# STM32H523 register map
File version: 1.2
CPU: CM33 r0p0, little endian, MPU, FPU, 4 interrupt priority bits
Registers are 32-bit, read-write, reset 0x0 unless marked. A register's access mark holds for its fields unless they carry their own. Offsets are from the block's base; [hi:lo] are bit positions; {n}, {i} and the like mark numbered series.

## DLYBOS1 — DLYB address block description
Base 0x4600F000
Same registers: DLYBSD1 0x46008400, DLYBSD1_S 0x56008400, DLYBOS1_S 0x5600F000
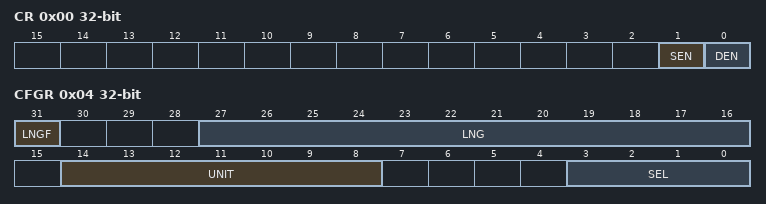
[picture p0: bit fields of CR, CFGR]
0x00 CR — DLYB control register
  [1] SEN — Sampler length enable bit
  [0] DEN — Delay block enable bit
0x04 CFGR — DLYB configuration register
  [31] LNGF ro — Length valid flag
  [27:16] LNG ro — Delay line length value
  [14:8] UNIT — Delay of a unit delay cell.
  [3:0] SEL — Phase for the output clock.

## DTS — DTS address block description
Base 0x40008C00
Same registers: DTS_S 0x50008C00
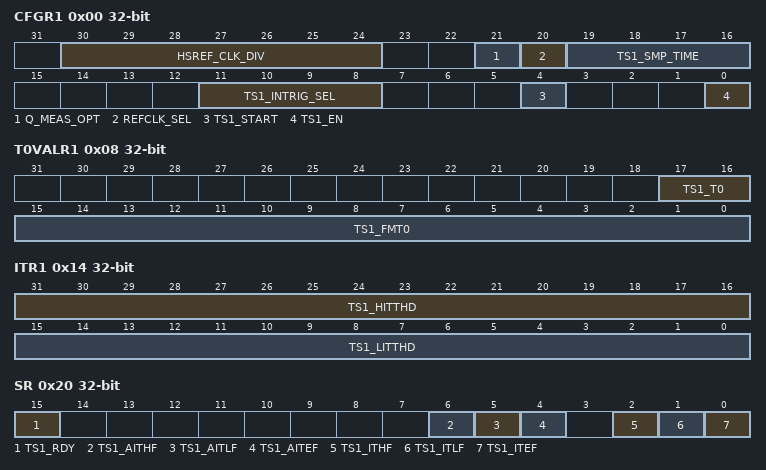
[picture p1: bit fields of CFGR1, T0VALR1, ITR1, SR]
0x00 CFGR1 — Temperature sensor configuration register 1
  [30:24] HSREF_CLK_DIV — High speed clock division ratio
  [21] Q_MEAS_OPT — Quick measurement option bit
  [20] REFCLK_SEL — Reference clock selection bit
  [19:16] TS1_SMP_TIME — Sampling time for temperature sensor 1
  [11:8] TS1_INTRIG_SEL — Input trigger selection bit for temperature sensor 1
  [4] TS1_START — Start frequency measurement on temperature sensor 1
  [0] TS1_EN — Temperature sensor 1 enable bit
0x08 T0VALR1 ro (reset mask 0xFFF00000) — Temperature sensor T0 value register 1
  [17:16] TS1_T0 — Engineering value of the T0 temperature for temperature sensor 1.
  [15:0] TS1_FMT0 — Engineering value of the frequency measured at T0 for
0x10 RAMPVALR ro reset not defined — Temperature sensor ramp value register
  [15:0] TS1_RAMP_COEFF — Engineering value of the ramp coefficient for the temperature sensor 1.
0x14 ITR1 — Temperature sensor interrupt threshold register 1
  [31:16] TS1_HITTHD — High interrupt threshold for temperature sensor 1
  [15:0] TS1_LITTHD — Low interrupt threshold for temperature sensor 1
0x1C DR — Temperature sensor data register
  [15:0] TS1_MFREQ — Value of the counter output value for temperature sensor 1
0x20 SR ro — Temperature sensor status register
  [15] TS1_RDY — Temperature sensor 1 ready flag
  [6] TS1_AITHF — Asynchronous interrupt flag for high threshold on temperature sensor 1
  [5] TS1_AITLF — Asynchronous interrupt flag for low threshold on temperature sensor 1
  [4] TS1_AITEF — Asynchronous interrupt flag for end of measure on temperature sensor 1
  [2] TS1_ITHF — Interrupt flag for high threshold on temperature sensor 1, synchronized on PCLK
  [1] TS1_ITLF — Interrupt flag for low threshold on temperature sensor 1, synchronized on PCLK.
  [0] TS1_ITEF — Interrupt flag for end of measurement on temperature sensor 1, synchronized on PCLK.
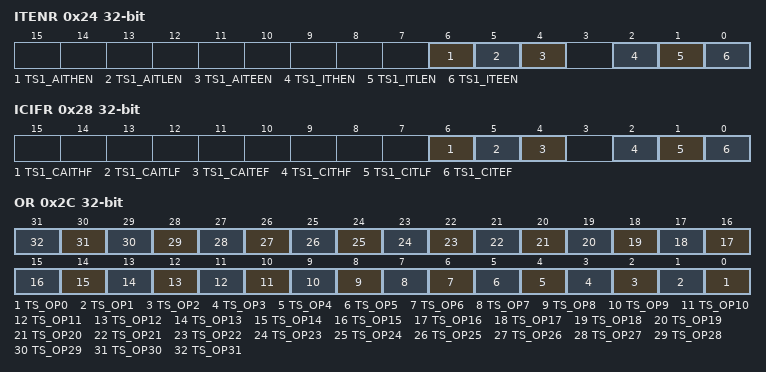
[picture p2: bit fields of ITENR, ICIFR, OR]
0x24 ITENR — Temperature sensor interrupt enable register
  [6] TS1_AITHEN — Asynchronous interrupt enable flag on high threshold for temperature sensor 1.
  [5] TS1_AITLEN — Asynchronous interrupt enable flag for low threshold on temperature sensor 1.
  [4] TS1_AITEEN — Asynchronous interrupt enable flag for end of measurement on temperature sensor 1
  [2] TS1_ITHEN — Interrupt enable flag for high threshold on temperature sensor 1, synchronized on PCLK.
  [1] TS1_ITLEN — Interrupt enable flag for low threshold on temperature sensor 1, synchronized on PCLK.
  [0] TS1_ITEEN — Interrupt enable flag for end of measurement on temperature sensor 1, synchronized on PCLK.
0x28 ICIFR — Temperature sensor clear interrupt flag register
  [6] TS1_CAITHF — Asynchronous interrupt clear flag for high threshold on temperature sensor 1
  [5] TS1_CAITLF — Asynchronous interrupt clear flag for low threshold on temperature sensor 1
  [4] TS1_CAITEF — Write once bit.
  [2] TS1_CITHF — Interrupt clear flag for high threshold on temperature sensor 1
  [1] TS1_CITLF — Interrupt clear flag for low threshold on temperature sensor 1
  [0] TS1_CITEF — Interrupt clear flag for end of measurement on temperature sensor 1
0x2C OR — Temperature sensor option register
  [n] TS_OP{n} (n=0..31) — general purpose option bits
